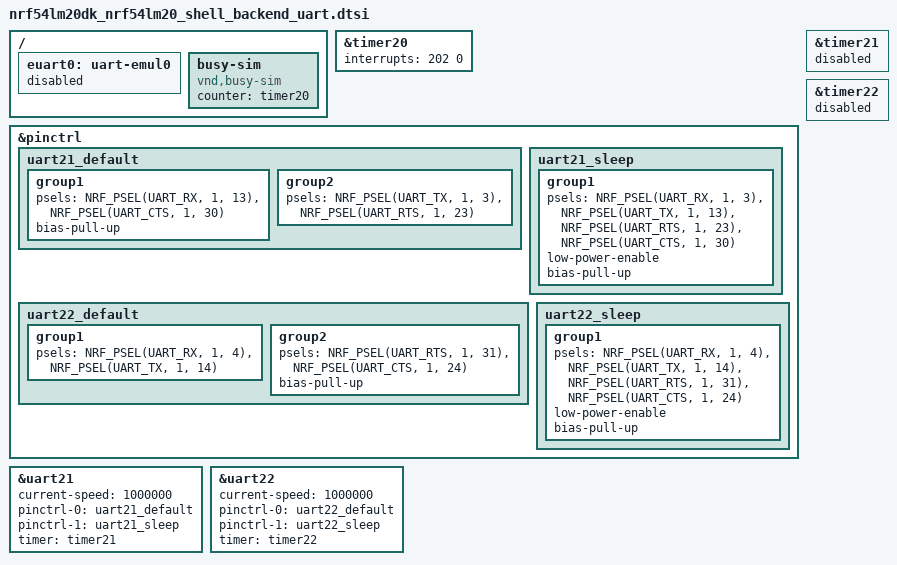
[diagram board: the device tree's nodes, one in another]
/*
 * Copyright (c) 2026 Nordic Semiconductor ASA
 *
 * SPDX-License-Identifier: Apache-2.0
 */

/* Test requires loopbacks:
 * P1.03 - P1.04
 * P1.13 - P1.14
 * P1.23 - P1.24
 * P1.30 - P1.31
 */

/ {
	euart0: uart-emul0 {
		status = "disabled";
	};

	busy-sim {
		compatible = "vnd,busy-sim";
		status = "okay";
		counter = <&timer20>;
	};
};

&timer20 {
	status = "okay";
	interrupts = <202 0>;
};

&pinctrl {
	uart21_default: uart21_default {
		group1 {
			psels = <NRF_PSEL(UART_RX, 1, 13)>,
				<NRF_PSEL(UART_CTS, 1, 30)>;
			bias-pull-up;
		};

		group2 {
			psels = <NRF_PSEL(UART_TX, 1, 3)>,
				<NRF_PSEL(UART_RTS, 1, 23)>;
		};
	};

	uart21_sleep: uart21_sleep {
		group1 {
			psels = <NRF_PSEL(UART_RX, 1, 3)>,
				<NRF_PSEL(UART_TX, 1, 13)>,
				<NRF_PSEL(UART_RTS, 1, 23)>,
				<NRF_PSEL(UART_CTS, 1, 30)>;
			low-power-enable;
			bias-pull-up;
		};
	};

	uart22_default: uart22_default {
		group1 {
			psels = <NRF_PSEL(UART_RX, 1, 4)>,
				<NRF_PSEL(UART_TX, 1, 14)>;
		};

		group2 {
			psels = <NRF_PSEL(UART_RTS, 1, 31)>,
				<NRF_PSEL(UART_CTS, 1, 24)>;
			bias-pull-up;
		};
	};

	uart22_sleep: uart22_sleep {
		group1 {
			psels = <NRF_PSEL(UART_RX, 1, 4)>,
				<NRF_PSEL(UART_TX, 1, 14)>,
				<NRF_PSEL(UART_RTS, 1, 31)>,
				<NRF_PSEL(UART_CTS, 1, 24)>;
			low-power-enable;
			bias-pull-up;
		};
	};
};

&timer21 {
	status = "reserved";
};

shell_uart: &uart21 {
	status = "okay";
	current-speed = <1000000>;
	pinctrl-0 = <&uart21_default>;
	pinctrl-1 = <&uart21_sleep>;
	pinctrl-names = "default", "sleep";
	timer = <&timer21>;
};

&timer22 {
	status = "reserved";
};

aux_uart: &uart22 {
	status = "okay";
	current-speed = <1000000>;
	pinctrl-0 = <&uart22_default>;
	pinctrl-1 = <&uart22_sleep>;
	pinctrl-names = "default", "sleep";
	timer = <&timer22>;
};
